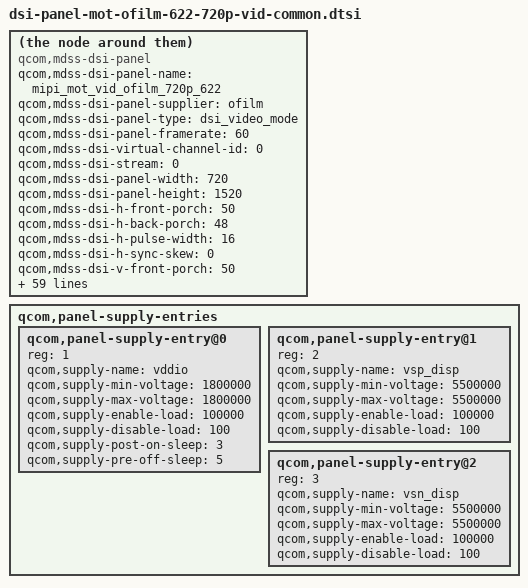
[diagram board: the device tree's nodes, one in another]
/* Copyright (c) 2016, The Linux Foundation. All rights reserved.
 *
 * This program is free software; you can redistribute it and/or modify
 * it under the terms of the GNU General Public License version 2 and
 * only version 2 as published by the Free Software Foundation.
 *
 * This program is distributed in the hope that it will be useful,
 * but WITHOUT ANY WARRANTY; without even the implied warranty of
 * MERCHANTABILITY or FITNESS FOR A PARTICULAR PURPOSE.  See the
 * GNU General Public License for more details.
 */

compatible = "qcom,mdss-dsi-panel";
qcom,mdss-dsi-panel-name = "mipi_mot_vid_ofilm_720p_622";
qcom,mdss-dsi-panel-supplier = "ofilm";
qcom,mdss-dsi-panel-type = "dsi_video_mode";
qcom,mdss-dsi-panel-framerate = <60>;
qcom,mdss-dsi-virtual-channel-id = <0>;
qcom,mdss-dsi-stream = <0>;
qcom,mdss-dsi-panel-width = <720>;
qcom,mdss-dsi-panel-height = <1520>;
/*484 MHz*/
qcom,mdss-dsi-h-front-porch = <50>;
qcom,mdss-dsi-h-back-porch = <48>;
qcom,mdss-dsi-h-pulse-width = <16>;
qcom,mdss-dsi-h-sync-skew = <0>;
qcom,mdss-dsi-v-front-porch = <50>;
qcom,mdss-dsi-v-back-porch = <37>;
qcom,mdss-dsi-v-pulse-width = <8>;
qcom,mdss-dsi-h-left-border = <0>;
qcom,mdss-dsi-h-right-border = <0>;
qcom,mdss-dsi-v-top-border = <0>;
qcom,mdss-dsi-v-bottom-border = <0>;
qcom,mdss-dsi-bpp = <24>;
qcom,mdss-dsi-underflow-color = <0xff>;
qcom,mdss-dsi-border-color = <0>;
qcom,mdss-dsi-on-command = [
	05 01 00 00 78 00 01 11
	39 00 00 00 00 00 03 50 5A 23
	39 00 00 00 00 00 03 90 CC 0C
	39 00 00 00 00 00 03 94 2C 01
	39 00 00 00 00 00 03 50 5a 2f
	15 00 00 00 00 00 02 50 00
	05 01 00 00 14 00 01 29];
qcom,mdss-dsi-off-command = [
	05 01 00 00 48 00 01 28
	05 01 00 00 14 00 01 10
	15 00 00 00 00 00 02 04 5A
	15 01 00 00 96 00 02 05 5A];


qcom,mdss-dsi-on-command-state = "dsi_lp_mode";
qcom,mdss-dsi-off-command-state = "dsi_lp_mode";

qcom,mdss-dsi-cabc-ui-command = [
	39 01 00 00 00 00 03 50 5A 23
	15 01 00 00 00 00 02 95 01
	39 01 00 00 00 00 03 50 5a 2f
	15 01 00 00 00 00 02 50 00];
qcom,mdss-dsi-cabc-ui-command-state = "dsi_hs_mode";
qcom,mdss-dsi-cabc-mv-command = [
	39 01 00 00 00 00 03 50 5A 23
	15 01 00 00 00 00 02 95 03
	39 01 00 00 00 00 03 50 5a 2f
	15 01 00 00 00 00 02 50 00];
qcom,mdss-dsi-cabc-mv-command-state = "dsi_hs_mode";
qcom,mdss-dsi-cabc-dis-command = [
	39 01 00 00 00 00 03 50 5A 23
	15 01 00 00 00 00 02 95 00
	39 01 00 00 00 00 03 50 5a 2f
	15 01 00 00 00 00 02 50 00];
qcom,mdss-dsi-cabc-dis-command-state = "dsi_hs_mode";
qcom,mdss-dsi-hbm-on-command = [
	39 01 00 00 00 00 03 50 5A 23
	39 01 00 00 00 00 03 90 FF 0F
	39 01 00 00 00 00 03 50 5a 2f
	15 01 00 00 00 00 02 50 00];
qcom,mdss-dsi-hbm-on-command-state = "dsi_hs_mode";
qcom,mdss-dsi-hbm-off-command = [
	39 01 00 00 00 00 03 50 5A 23
	39 01 00 00 00 00 03 90 CC 0C
	39 01 00 00 00 00 03 50 5a 2f
	15 01 00 00 00 00 02 50 00];
qcom,mdss-dsi-hbm-off-command-state = "dsi_hs_mode";
qcom,mdss-dsi-hbm-type = "lcd-dcs-wled";

qcom,mdss-dsi-h-sync-pulse = <0>;
qcom,mdss-dsi-traffic-mode = "burst_mode";
qcom,mdss-dsi-bllp-eof-power-mode;
qcom,mdss-dsi-bllp-power-mode;
qcom,mdss-dsi-lane-0-state;
qcom,mdss-dsi-lane-1-state;
qcom,mdss-dsi-lane-2-state;
qcom,mdss-dsi-lane-3-state;
qcom,mdss-dsi-panel-timings-phy-v2 = [
	1F 1C 04 06 03 03 04 a0
	1F 1C 04 06 03 03 04 a0
	1F 1C 04 06 03 03 04 a0
	1F 1C 04 06 03 03 04 a0
	1F 0F 04 06 03 03 04 a0];
qcom,mdss-dsi-t-clk-post = <0x0A>;
qcom,mdss-dsi-t-clk-pre = <0x1F>;
qcom,mdss-dsi-bl-min-level = <1>;
qcom,mdss-dsi-bl-max-level = <2047>;
qcom,mdss-dsi-dma-trigger = "trigger_sw";
qcom,mdss-dsi-mdp-trigger = "none";
qcom,mdss-dsi-bl-pmic-control-type = "bl_ctrl_wled";
qcom,mdss-dsi-reset-sequence = <0 1>, <1 35>;
qcom,mdss-dsi-lp11-init;
qcom,mdss-dsi-tx-eot-append;
qcom,mdss-dsi-no-panel-on-read-support;
qcom,mdss-panel-reg-read-lp-enable;

qcom,panel-supply-entries {
	#address-cells = <1>;
	#size-cells = <0>;

	qcom,panel-supply-entry@0 {
		reg = <1>;
		qcom,supply-name = "vddio";
		qcom,supply-min-voltage = <1800000>;
		qcom,supply-max-voltage = <1800000>;
		qcom,supply-enable-load = <100000>;
		qcom,supply-disable-load = <100>;
		qcom,supply-post-on-sleep = <3>;
		qcom,supply-pre-off-sleep = <5>;
	};


	qcom,panel-supply-entry@1 {
		reg = <2>;
		qcom,supply-name = "vsp_disp";
		qcom,supply-min-voltage = <5500000>;
		qcom,supply-max-voltage = <5500000>;
		qcom,supply-enable-load = <100000>;
		qcom,supply-disable-load = <100>;
	};

	qcom,panel-supply-entry@2 {
		reg = <3>;
		qcom,supply-name = "vsn_disp";
		qcom,supply-min-voltage = <5500000>;
		qcom,supply-max-voltage = <5500000>;
		qcom,supply-enable-load = <100000>;
		qcom,supply-disable-load = <100>;
	};
};
